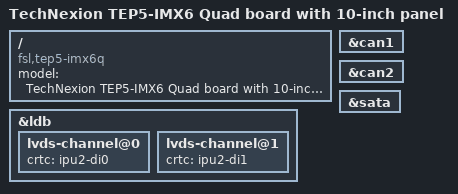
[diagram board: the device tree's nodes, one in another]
/*
 * Copyright 2018 TechNexion Ltd.
 *
 * Author: Wig Cheng  <wig.cheng@technexion.com>
 *	   Richard Hu <richard.hu@technexion.com>
 *
 * The code contained herein is licensed under the GNU General Public
 * License. You may obtain a copy of the GNU General Public License
 * Version 2 or later at the following locations:
 *
 * http://www.opensource.org/licenses/gpl-license.html
 * http://www.gnu.org/copyleft/gpl.html
 */

/dts-v1/;

#include <dt-bindings/interrupt-controller/irq.h>
#include "imx6q.dtsi"
#include "imx6qdl-tep5.dtsi"

/ {
	model = "TechNexion TEP5-IMX6 Quad board with 10-inch panel";
	compatible = "fsl,tep5-imx6q", "fsl,imx6q";
};

&ldb {
	lvds-channel@0 {
		crtc = "ipu2-di0";
	};
	lvds-channel@1 {
		crtc = "ipu2-di1";
	};
};

&can1{
	status = "okay";
};

&can2{
	status = "okay";
};

#if 0
&mxcfb3 {
	status = "okay";
};

&mxcfb4 {
	status = "okay";
};
#endif

&sata {
	status = "okay";
};
